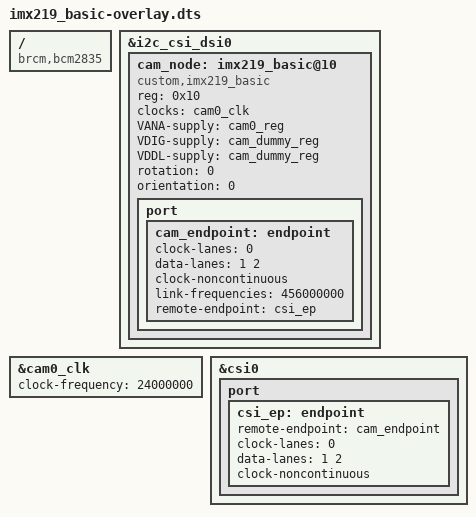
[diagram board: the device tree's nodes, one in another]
// SPDX-License-Identifier: GPL-2.0-only
// Simplified: hardcoded to CAM0 always, no cam0/cam1 override switch.

/dts-v1/;
/plugin/;

/{
    compatible = "brcm,bcm2835";

    fragment@0 {
        target = <&i2c_csi_dsi0>;
        __overlay__ {
            #address-cells = <1>;
            #size-cells = <0>;
            status = "okay";

            cam_node: imx219_basic@10 {
                compatible = "custom,imx219_basic";
                reg = <0x10>;
                status = "okay";

                clocks = <&cam0_clk>;
                clock-names = "xclk";

                VANA-supply = <&cam0_reg>;
                VDIG-supply = <&cam_dummy_reg>;
                VDDL-supply = <&cam_dummy_reg>;

                rotation = <0>;
                orientation = <0>;

                port {
                    cam_endpoint: endpoint {
                        clock-lanes = <0>;
                        data-lanes = <1 2>;
                        clock-noncontinuous;
                        link-frequencies = /bits/ 64 <456000000>;
                    };
                };
            };
        };
    };

    fragment@1 {
        target = <&cam0_clk>;
        __overlay__ {
            status = "okay";
            clock-frequency = <24000000>;
        };
    };

    fragment@2 {
        target = <&csi0>;
        __overlay__ {
            status = "okay";

            port {
                csi_ep: endpoint {
                    remote-endpoint = <&cam_endpoint>;
                    clock-lanes = <0>;
                    data-lanes = <1 2>;
                    clock-noncontinuous;
                };
            };
        };
    };

    __overrides__ {
        rotation = <&cam_node>,"rotation:0";
        orientation = <&cam_node>,"orientation:0";
    };
};

&cam_endpoint {
    remote-endpoint = <&csi_ep>;
};
